# TC37XPD register map
Vendor: Infineon; Series: ATVMC; File version: 100
CPU: other r0p0, little endian, MPU, FPU, vendor SysTick, 4 interrupt priority bits
Registers are 32-bit, read-write, reset 0x0 unless marked. A register's access mark holds for its fields unless they carry their own. Offsets are from the block's base; [hi:lo] are bit positions; lines under a group give offsets from that group; {n}, {i} and the like mark numbered series; 'fields as' and 'values as' point back to an identical list.

## CAN1 — CAN
Base 0xF0210000
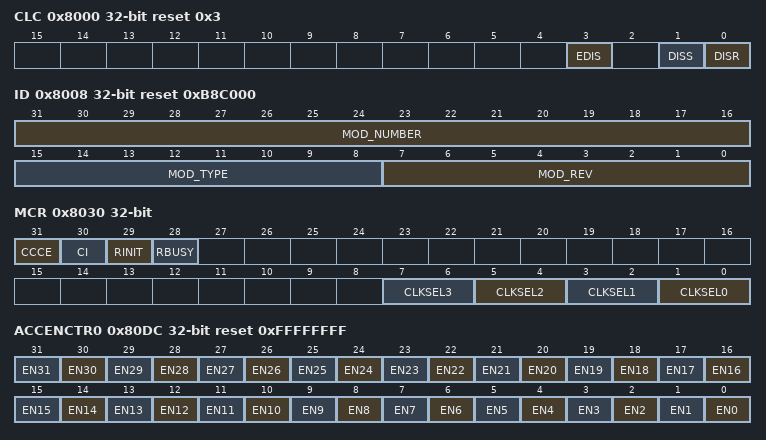
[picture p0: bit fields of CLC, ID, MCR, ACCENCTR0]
0x8000 CLC access per field reset 0x3 — CAN Clock Control Register resetvalue={Application Reset:0x3}
  [3] EDIS rw — Sleep Mode Disable Control EDIS. Used to control module s sleep mode.
  [1] DISS ro — Module Disable Status Bit DISS. Bit indicates the current status of the module.
  [0] DISR rw — Module Disable Request Bit DISR. Used for enable disable control of the module. The synchronous and asynchronous clock is switched on off Note that no register access is possible to any register while module is disabled. A disable request is granted if the M CAN clock is disabled or all M CAN nodes acknowledge the disable request.
0x8008 ID ro reset 0xB8C000 (reset mask 0xFFFFFF00) — Module Identification Register resetvalue={Application Reset:0x0B8C000}
  [31:16] MOD_NUMBER — Module Number Value MOD NUMBER. This bit field defines the MCMCAN module identification number 00B8 .
  [15:8] MOD_TYPE — Module Type MOD TYPE
  [7:0] MOD_REV — Module Revision Number MOD REV. MOD REV defines the revision number. The value of a module revision starts with 01 H first revision .
0x8030 MCR access per field — Module Control Register resetvalue={Application Reset:0x0}
  [31] CCCE rw — Clock and RAM Change Enable CCCE. Needs to be set to enable and disable the clocks.
  [30] CI rw — Change Init CI. Needs to be set to enable and disable clocks.
  [29] RINIT rw — RAM Init RINIT. This bit is not implemented in TC39x A step silicon. This bit is MCR.CI and MCR.CCCE protected. This bit starts the initialization of the RAM block to all 0x0. The RAM initialization is started only when this bit is changed from 0b to 1b and also RBUSY is 0b.
  [28] RBUSY ro — RAM BUSY RBUSY. This bit is not implemented in TC39x A step silicon. This bit shows that the RAM Initialization is running. This bit is set back to 0b by hardware when the RAM intialization is completed.
  [2n+1:2n] CLKSEL{n} rw (n=0..3) — Clock Select {n} CLKSEL{n}. This bitfield is MCR.CI and MCR.CCCE protected.
0x80DC ACCENCTR0 reset 0xFFFFFFFF — Access Enable Register Control 0 resetvalue={Application Reset:0x0FFFFFFFF}
  [n] EN{n} (n=0..31) — Access Enable for Master TAG ID 31 EN31. This bit enables write access to the module kernel addresses for transactions with the Master TAG ID y
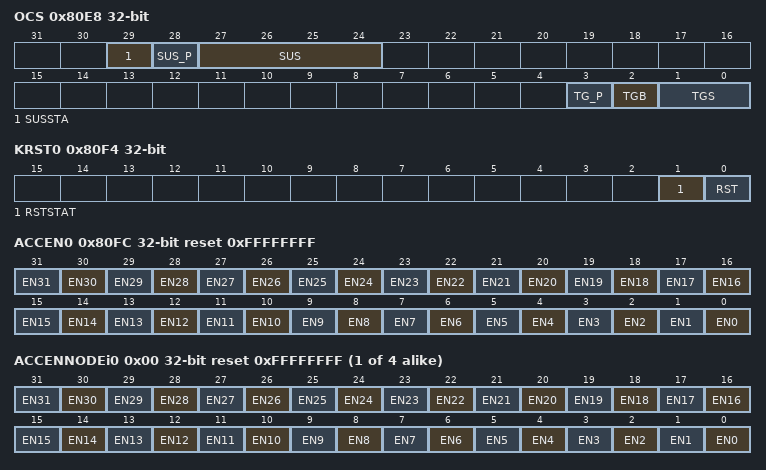
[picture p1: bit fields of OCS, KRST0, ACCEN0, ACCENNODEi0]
0x80E8 OCS access per field — OCDS Control and Status resetvalue={Debug Reset:0x0}
  [29] SUSSTA ro — Suspend State SUSSTA
  [28] SUS_P wo — SUS Write Protection SUS P. SUS is only written when SUS P is 1 otherwise unchanged. Read as 0.
  [27:24] SUS rw — OCDS Suspend Control SUS. Controls the sensitivity to the suspend signal coming from the OCDS Trigger Switch OTGS
  [3] TG_P wo — TGS TGB Write Protection TG P. TGS and TGB are only written when TG P is 1 otherwise unchanged. Read as 0.
  [2] TGB rw — OTGB0 1 Bus Select TGB
  [1:0] TGS rw — Trigger Set for OTGB0 1 TGS
0x80EC KRSTCLR wo — Kernel Reset Status Clear Register resetvalue={Application Reset:0x0}
  [0] CLR — Kernel Reset Status Clear CLR. Read always as 0.
0x80F0 KRST1 — Kernel Reset Register 1 resetvalue={Application Reset:0x0}
  [0] RST — Kernel Reset RST. This reset bit can be used to request for a kernel reset. The kernel reset will be executed if the reset bits of both kernel reset registers is set. The RST bit will be cleared reset to 0 by the BPI FPI after the kernel reset was executed.
0x80F4 KRST0 access per field — Kernel Reset Register 0 resetvalue={Application Reset:0x0}
  [1] RSTSTAT ro — Kernel Reset Status RSTSTAT. This bit indicates wether a kernel reset was executed or not. This bit is set by the BPI FPI after the execution of a kernel reset in the same clock cycle both reset bits. This bit can be cleared by writing with 180 1 180 to the CLR bit in the related KRSTCLR register.
  [0] RST rw — Kernel Reset RST. This reset bit can be used to request for a kernel reset. The kernel reset will be executed if the reset bits of both kernel registers are set. The RST bit will be cleared reset to 180 0 180 by the BPI FPI after the kernel reset was executed.
0x80FC ACCEN0 reset 0xFFFFFFFF — Access Enable Register 0 resetvalue={Application Reset:0x0FFFFFFFF}
  [n] EN{n} (n=0..31) — Access Enable for Master TAG ID 31 EN31. This bit enables write access to the module kernel addresses for transactions with the Master TAG ID y.
{0x8100+0x400*i} N[{i}] (i=0..3) group
  0x00 ACCENNODEi0 reset 0xFFFFFFFF — Access Enable Register CAN Node 0 0 resetvalue={Application Reset:0x0FFFFFFFF}
    fields as ACCENCTR0
  0x08 STARTADRi — Start Address Node 0 resetvalue={Application Reset:0x0}
    [15:2] START — Message RAM start START. The address within the RAM area of the MCMCAN of node i where the message RAM to be protected starts
  0x0C ENDADRi — End Address Node 0 resetvalue={Application Reset:0x0}
    [15:2] END — Message RAM end END. The address within the RAM area of the MCMCAN of node i where the message RAM to be protected ends
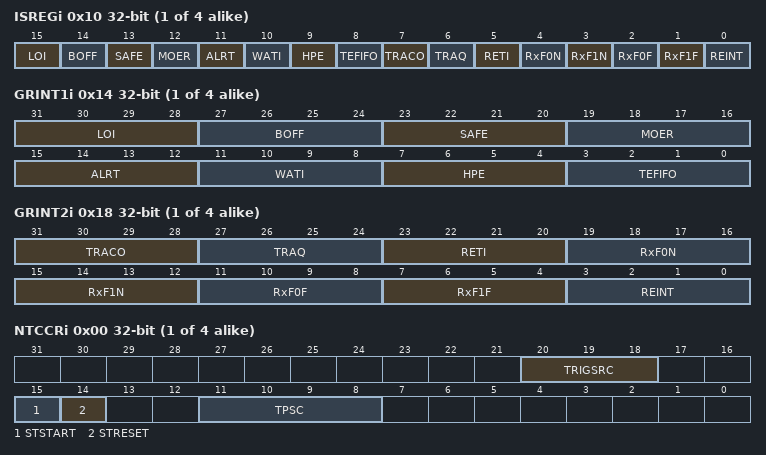
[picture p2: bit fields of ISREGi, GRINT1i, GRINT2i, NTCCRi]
  0x10 ISREGi ro — Interrupt Signalling Register 0 resetvalue={Application Reset:0x0}
    [15] LOI — Last Error Interrupt LOI
    [14] BOFF — Bus Off Interrupt BOFF
    [13] SAFE — The safety counter interrupt ELO SAFE
    [12] MOER — Module error interrupt MOER
    [11] ALRT — An alert interrupt ALRT
    [10] WATI — A watermark interrupt has been reached WATI
    [9] HPE — A high priority event interrupt HPE
    [8] TEFIFO — A Transmit Event FIFO Incident interrupt TEFIFO
    [7] TRACO — A transmission control event interrupt TRACO
    [6] TRAQ — A transmission queue event interrupt TRAQ
    [5] RETI — A receive timeout event interrupt RETI
    [4] RxF0N — Receive FIFO0 got a new message interrupt RxF0N
    [3] RxF1N — Receive FIFO1 got a new message interrupt RxF1N
    [2] RxF0F — Receive FIFO0 is full interrupt RxF0F
    [1] RxF1F — Receive FIFO1 is full interrupt RxF1F
    [0] REINT — A message stored in a receive buffer interrupt REINT
  0x14 GRINT1i — Interrupt routing for Groups 1 0 resetvalue={Application Reset:0x0}
    [31:28] LOI — Last Error Interrupts LOI. The interrupt sources IR.PED Protocol Error in Data Phase and IR.PEA Protocol Error in Arbitration Phase are signalled here.
    [27:24] BOFF — Bus Off has been reached BOFF. Mapped to IRi.BO flag indication the change in Bus Off status. To get out of bus off the CCCRn.INIT bit has to be reset.
    [23:20] SAFE — Safety counter overflow SAFE. The interrupt node for IR.ELO showing a safety counter overflow
    [19:16] MOER — Module errors MOER. IR.WDI watchdog interrupt and IR.MRAF message RAM access failure are mapped here.
    [15:12] ALRT — ALERTS ALRT. All kind of alerts are mapped here. IR.EW warning status IR.EP error passive IR.TSW timestamp wrap around IR.TEFL Transmit Event FIFO Element Lost IR.RF0L Receive FIFO 0 Message Lost IR.RF1L Receive FIFO 1 Message Lost . The following TTCAN error messages and warnings are also shown here TTIR. CER Configuration Error TTIR.AW Application Watchdog TTIR.WT Watch Trigger TTIR.IWT Initialization Watch Trigger TTIR.ELC Error Level Changed TTIR.SE2 Scheduling Error 2 TTIR.SE1 Scheduling Error TTIR.TXO Tx Count Overflow TTIR.TXU TX Count Underflow TTIR.GTE Global Time Error TTIR.GTD Global Time Discontinuity and TTIR.GTW Global Time Wrap
    [11:8] WATI — Watermark interrupts WATI. are mapped here IR.TEFW Transmit FIFO warning interrupt reached IR.RF1W Receive FIFO 1 warning interrupt reached . IR.RF0W Receive FIFO 0 warning interrupt reached
    [7:4] HPE — High Priority Events HPE. are mapped here giving IR.HPM an interrupt level
    [3:0] TEFIFO — Transmit Event FIFO Incidents TEFIFO. are mapped here. IR.TEFF Transmit Event FIFO Full and IR.TEFN Transmit Event FIFO New Entry
  0x18 GRINT2i — Interrupt routing for Groups 2 0 resetvalue={Application Reset:0x0}
    [31:28] TRACO — Interrupts of the transmission control TRACO. can be assigned here. IR.TCF Transmission Cancellation Finished and IR.TF Transmission Completed . As an additional information the copy of a local time event is shown here with TTIR.SWT Stop Watch Event . Further on the TTIR.TTMI Trigger Time Event Internal TTIR.RTMI Register Time Mark TTIR.SOG Start of Gap TTIR.CSM Change of Synchronization Mode TTIR.SMC Start Matrix Cycle and TTIR.SBC Start of Basic Cycle are shown here.
    [27:24] TRAQ — Transmission Queue Events TRAQ. can be assigned here. IR.TFE Transmission FIFO Empty
    [23:20] RETI — Receive Timeouts RETI. can be assigned here. IR.TOO time out event and TE Timer Event
    [19:16] RxF0N — IR.RF0N RxF0N. Receive FIFO0 new message assigned to an interrupt node
    [15:12] RxF1N — IR.RF1N RxF1N. Receive FIFO1 new message assigned to an interrupt node
    [11:8] RxF0F — IR.RF0F RxF0F. Receive FIFO0 full interrupt assigned to an interrupt node
    [7:4] RxF1F — IR.RF1F RxF1F. Receive FIFO1 full interrupt assigned to an interrupt node
    [3:0] REINT — Message stored in dedicated receive buffer interrupt IR.DRX REINT. is assigned to interrupt node.
  0x20 NT group
    0x00 NTCCRi — Node 0 Timer Clock Control Register resetvalue={Application Reset:0x0}
      [20:18] TRIGSRC — Trigger Source TRIGSRC. This bit selects the trigger source for the different modes in the node timer.
      [15] STSTART — Stamping Start STSTART. This bit is not implemented in TC39x A step silicon. This bit starts the external timer used for CAN FD messages. The source and the prescaler are identical to the timers A B C.
      [14] STRESET — Stamping Reset STRESET. This bit is not implemented in TC39x A step silicon. This bit gives the possibility to reset the time stamp for CAN FD messages.
      [11:8] TPSC — Timer Prescaler TPSC. The duration of one timer clock is given by TPSC 160 160 1 CAN bit times for all NTCCRi.TRIGSRC settings.
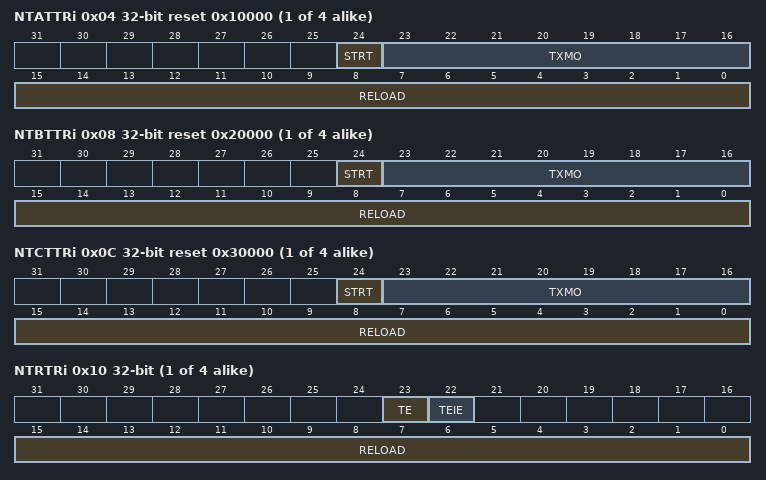
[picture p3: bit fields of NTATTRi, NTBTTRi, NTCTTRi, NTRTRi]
    0x04 NTATTRi access per field reset 0x10000 — Node 0 Timer A Transmit Trigger Register resetvalue={Application Reset:0x10000}
      [24] STRT rw — Timer Start STRT. This bit field controls the operation of the timer.
      [23:16] TXMO ro — Transmit Message Object TXMO. This transmit trigger is fixed to transmit buffer 1
      [15:0] RELOAD rw — Reload Value RELOAD. This bit field contains the reload value for the timer. The timer will restart when RELOAD is written.
    0x08 NTBTTRi access per field reset 0x20000 — Node 0 Timer B Transmit Trigger Register resetvalue={Application Reset:0x20000}
      [24] STRT rw — Timer Start STRT. This bit field controls the operation of the timer.
      [23:16] TXMO ro — Transmit Message Object TXMO. This transmit object is fixed to transmit buffer 2
      [15:0] RELOAD rw — Reload Value RELOAD. This bit field contains the reload value for the timer. The timer will restart when RELOAD is written.
    0x0C NTCTTRi access per field reset 0x30000 — Node 0 Timer C Transmit Trigger Register resetvalue={Application Reset:0x30000}
      [24] STRT rw — Timer Start STRT. This bit field controls the operation of the timer.
      [23:16] TXMO ro — Transmit Message Object TXMO. This transmit trigger is fixed to transmit buffer 3
      [15:0] RELOAD rw — Reload Value RELOAD. This bit field contains the reload value for the timer. The timer will restart when RELOAD is written.
    0x10 NTRTRi — Node 0 Timer Receive Timeout Register resetvalue={Application Reset:0x0}
      [23] TE — Timer Event TE. This flag is set on a node timer transition from 1 to 0 in Receive Timeout Mode. This bit must be reset i.e Write to 8216 0 8217 by software writing a 8216 1 8217 has no effect. An interrupt request is generated if TEIE 1.
      [22] TEIE — Timer Event Interrupt Enable TEIE. This bit enables the node timer event interrupt of CAN node i. Bit field GRINT2.RETI selects the interrupt output line which becomes activated at this type of interrupt.
      [15:0] RELOAD — Reload Value RELOAD. This bit field contains the reload value for the timer. The timer will start when RELOAD 8800 0 is written. After half the time of the RELOAD value the interrupt flags of the receive buffers will be cleared automatically to ensure that no message receive will be missed.
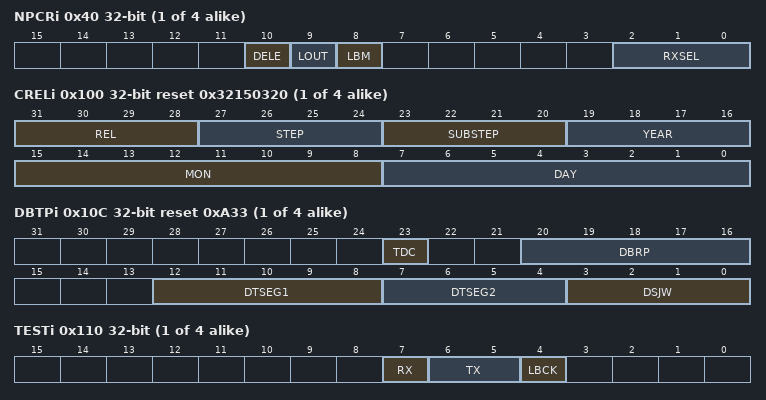
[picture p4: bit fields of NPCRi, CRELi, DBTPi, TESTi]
  0x40 NPCRi — Node 0 Port Control Register resetvalue={Application Reset:0x0}
    [10] DELE — Enable destructive read on ECR0.CEL DELE. If this bit is set the destructive read on ECRi.CEL and on the PSR register takes place. Meaning that with read access on ECRi the CEL is reset. The same is true for the PSR register for the bits PXE RFDF RBRS RESI LEC and DLEC. After the destructive read it is advised to reset the bit again.
    [9] LOUT — Loop Back Mode Out LOUT. This bit is not implemented in TC39x A step silicon. The loop back bus is switched to the external CAN bus of the node.
    [8] LBM — Loop Back Mode LBM
    [2:0] RXSEL — Receive Select RXSEL. RXSEL selects one out of 8 possible receive inputs. The CAN receive signal is performed by the selected input. see the device related chapter for RXSEL
  0x100 CRELi ro reset 0x32150320 (reset mask 0xFFFFFFFC) — Core Release Register 0 resetvalue={Application Reset:0x32150320,Application Reset:0x32150323,Application Reset:0x32150320}
    [31:28] REL — Core Release REL. One digit BCD coded.
    [27:24] STEP — Step of Core Release STEP. One digit BCD coded.
    [23:20] SUBSTEP — Sub step of Core Release SUBSTEP. One digit BCD coded.
    [19:16] YEAR — Time Stamp Year
    [15:8] MON — Time Stamp Month
    [7:0] DAY — Time Stamp Day
  0x104 ENDNi ro reset 0x87654321 — Endian Register 0 resetvalue={Application Reset:0x087654321}
    [31:0] ETV — Endianness Test Value ETV. The endianness test value is 0x87654321.
  0x10C DBTPi reset 0xA33 — Data Bit Timing Prescaler Register 0 resetvalue={Application Reset:0x0A33}
    [23] TDC — Transmitter Delay Compensation TDC. This bitfield is CCE and INIT protected. Writes will only have effect if both bits are set.
    [20:16] DBRP — Data Baud Rate Prescaler DBRP. This bitfield is CCE and INIT protected. Writes will only have effect if both bits are set. The value by which the oscillator frequency is divided for generating the bit time quanta. The bit time is built up from a multiple of this quanta. Valid values for the Baud Rate Prescaler are 8201 0 to 31. The actual interpretation by the hardware of this value is such that one more than the value programmed here is used.
    [12:8] DTSEG1 — Data time segment before sample point DTSEG1. This bitfield is CCE and INIT protected. Writes will only have effect if both bits are set. Valid values are 0 to 31. The actual interpretation by the hardware of this value is such that one more than the programmed value is used.
    [7:4] DTSEG2 — Data time segment after sample point DTSEG2. This bitfield is CCE and INIT protected. Writes will only have effect if both bits are set. Valid values are 0 to 15. The actual interpretation by the hardware of this value is such that one more than the programmed value is used.
    [3:0] DSJW — Data Re Synchronization Jump Width DSJW. This bitfield is CCE and INIT protected. Writes will only have effect if both bits are set. Valid values are 0 to 15. The actual interpretation by the hardware of this value is such that one more than the value programmed here is used.
  0x110 TESTi access per field (reset mask 0xFFFFFF7F) — Test Register 0 resetvalue={Application Reset:0x0}
    [7] RX ro — Receive Pin RX. Monitors the actual value of RX pin.
    [6:5] TX rw — Control of Transmit Pin TX. This bitfield is CCE and INIT protected. Writes will only have effect if both bits are set.
    [4] LBCK rw — Loop Back Mode LBCK. This bitfield is CCE and INIT protected. Writes will only have effect if both bits are set. This is the external loop back mode visible on the outside.
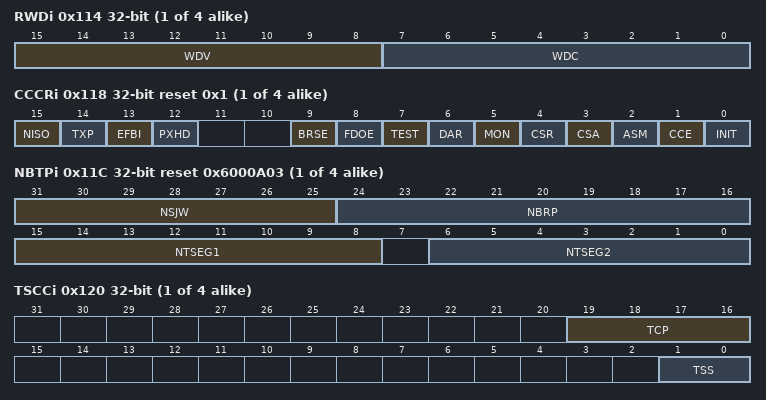
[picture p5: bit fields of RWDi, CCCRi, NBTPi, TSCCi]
  0x114 RWDi access per field — RAM Watchdog 0 resetvalue={Application Reset:0x0}
    [15:8] WDV ro — Watchdog Value WDV. Actual Message RAM Watchdog Counter Value.
    [7:0] WDC rw — Watchdog Configuration WDC. This bitfield is CCE and INIT protected. Writes will only have effect if both bits are set. Start value of the Message RAM Watchdog Counter. With the reset value of 00 the counter is disabled.
  0x118 CCCRi access per field reset 0x1 — CC Control Register 0 resetvalue={Application Reset:0x1}
    [15] NISO rw — Non ISO Operation NISO. If this bit is set the M CAN uses the CAN FD frame format as specified by the Bosch CAN FD Specification V1.0.
    [14] TXP rw — Transmit Pause TXP. This bitfield is CCE and INIT protected. Writes will only have effect if both bits are set. If this bit is set the M CAN pauses for two CAN bit times before starting the next transmission after itself has successfully transmitted a frame see CROSSREFERENCE .
    [13] EFBI rw — Edge Filtering during Bus Integration EFBI. This bitfield is CCE and INIT protected. Writes will only have effect if both bits are set.
    [12] PXHD rw — Protocol Exception Handling Disable PXHD. This bitfield is CCE and INIT protected. Writes will only have effect if both bits are set.
    [9] BRSE rw — Bit Rate Switch Enable BRSE. This bitfield is CCE and INIT protected. Writes will only have effect if both bits are set.
    [8] FDOE rw — FD Operation Enable FDOE. This bitfield is CCE and INIT protected. Writes will only have effect if both bits are set.
    [7] TEST rw — Test Mode Enable TEST. The TEST register can only be set if CCE INIT and TEST are set. Writes to test will only have effect if all three bits are set.
    [6] DAR rw — Disable Automatic Retransmission DAR. This bitfield is CCE and INIT protected. Writes will only have effect if both bits are set.
    [5] MON rw — Bus Monitoring Mode MON. Bit MON can only be set by the Host when both CCE and INIT are set to 8216 1 8217 . The bit can be reset by the Host at any time. The bus monitoring mode corresponds to the Analyzer Mode of the MultiCAN module.
    [4] CSR rw — Clock Stop Request CSR
    [3] CSA ro — Clock Stop Acknowledge CSA
    [2] ASM rw — Restricted Operation Mode ASM. Bit ASM can only be set by the Host when both CCE and INIT are set to 8216 1 8217 . In can also be set by the M CAN . The bit can be reset by the Host at any time. For a description of the Restricted Operation Mode see paragraph Restricted Operation Mode.
    [1] CCE rw — Configuration Change Enable CCE
    [0] INIT rw — Initialization INIT. Due to the synchronization mechanism between the two clock domains there may be a delay until the value written to INIT can be read back. Therefore the programmer has to assure that the previous value written to INIT has been accepted by reading INIT before setting INIT to a new value.
  0x11C NBTPi reset 0x6000A03 — Nominal Bit Timing Prescaler Register 0 resetvalue={Application Reset:0x6000A03}
    [31:25] NSJW — Re Synchronization Jump Width NSJW. This bitfield is CCE and INIT protected. Writes will only have effect if both bits are set. Valid values are 0 to 127. The actual interpretation by the hardware of this value is such that one more than the value programmed here is used.
    [24:16] NBRP — Baud Rate Prescaler NBRP. This bitfield is CCE and INIT protected. Writes will only have effect if both bits are set. The value by which the oscillator frequency is divided for generating the bit time quanta. The bit time is built up from a multiple of this quanta. Valid values for the Baud Rate Prescaler are 0 to 511. The actual interpretation by the hardware of this value is such that one more than the value programmed here is used.
    [15:8] NTSEG1 — Nominal Time segment before sample point NTSEG1. This bitfield is CCE and INIT protected. Writes will only have effect if both bits are set. Valid values are 1 to 255. The actual interpretation by the hardware of this value is such that one more than the programmed value is used.
    [6:0] NTSEG2 — Nominal Time segment after sample point NTSEG2. This bitfield is CCE and INIT protected. Writes will only have effect if both bits are set. Valid values are 1 to 127. The actual interpretation by the hardware of this value is such that one more than the programmed value is used.
  0x120 TSCCi — Timestamp Counter Configuration 0 resetvalue={Application Reset:0x0}
    [19:16] TCP — Timestamp Counter Prescaler TCP. This bitfield is CCE and INIT protected. Writes will only have effect if both bits are set. Configures the timestamp and timeout counters time unit in multiples of CAN bit times 8201 1 8230 16 8201 . The actual interpretation by the hardware of this value is such that one more than the value programmed here is used. With CAN FD an external counter is required for timestamp generation TSS 8220 10 8221
    [1:0] TSS — Time segment before sample point TSS. This bitfield is CCE and INIT protected. Writes will only have effect if both bits are set.
  0x124 TSCVi — Timestamp Counter Value 0 resetvalue={Application Reset:0x0}
    [15:0] TSC — Timestamp Counter TSC. The internal external Timestamp Counter value is captured on start of frame both Rx and Tx . When TSCC.TSS 8220 01 8221 the Timestamp Counter is incremented in multiples of CAN bit times 8201 1 8230 16 8201 depending on the configuration of TSCC.TCP. A wrap around sets interrupt flag IR.TSW. Write access resets the counter to zero. When TSCC.TSS 160 160 8220 10 8221 TSC reflects the external Timestamp Counter value. A write access has no impact. A 8220 wrap around 8221 is a change of the Timestamp Counter value from non zero to zero not caused by write access to TSCV.
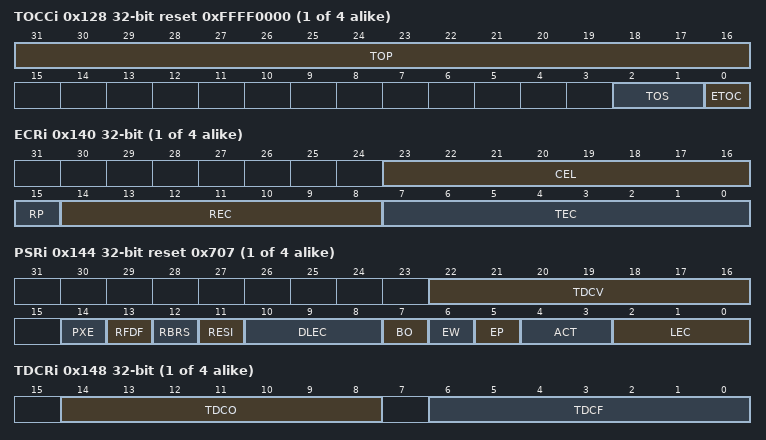
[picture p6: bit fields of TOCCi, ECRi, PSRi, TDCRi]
  0x128 TOCCi reset 0xFFFF0000 — Timeout Counter Configuration 0 resetvalue={Application Reset:0x0FFFF0000}
    [31:16] TOP — Timeout Period TOP. This bitfield is CCE and INIT protected. Writes will only have effect if both bits are set. Start value of the Timeout Counter down counter . Configures the Timeout Period.
    [2:1] TOS — Timeout Select TOS. This bitfield is CCE and INIT protected. Writes will only have effect if both bits are set. When operating in Continuous mode a write to TOCV presets the counter to the value configured by TOCC.TOP and continues down counting. When the Timeout Counter is controlled by one of the FIFOs an empty FIFO presets the counter to the value configured by TOCC.TOP. Down counting is started when the first FIFO element is stored.
    [0] ETOC — Enable Timeout Counter ETOC. This bitfield is CCE and INIT protected. Writes will only have effect if both bits are set. For use of timeout function with CAN FD see chapter Timeout Counter.
  0x12C TOCVi reset 0xFFFF — Timeout Counter Value 0 resetvalue={Application Reset:0x0FFFF}
    [15:0] TOC — Timeout Counter TOC. The Timeout Counter is decremented in multiples of CAN bit times 8201 1 8230 16 8201 depending on the configuration of TSCC.TCP. When decremented to zero interrupt flag IR.TOO is set and the Timeout Counter is stopped. Start and reset restart conditions are configured via TOCC.TOS. Any write access will lead to clearing of the counter.
  0x140 ECRi ro — Error Counter Register 0 resetvalue={Application Reset:0x0}
    [23:16] CEL — CAN Error Logging CEL. The counter is incremented each time when a CAN protocol error causes the Transmit Error Counter or the Receive Error Counter to be incremented. It is reset by read access to CEL. The counter stops at 0xFF the next increment of TEC or REC sets interrupt flag IR.ELO. The counter is reset on read if the bit NPCRi.DELE is set for the node.
    [15] RP — Receive Error Passive RP
    [14:8] REC — Receive Error Counter REC. Actual state of the Receive Error Counter values between 0 and 127 When CCCR.ASM is set the CAN protocol controller does not increment TEC and REC when a CAN protocol error is detected but CEL is still incremented.
    [7:0] TEC — Transmit Error Counter TEC. Actual state of the Transmit Error Counter values between 0 and 255 When CCCR.ASM is set the CAN protocol controller does not increment TEC and REC when a CAN protocol error is detected but CEL is still incremented.
  0x144 PSRi ro reset 0x707 — Protocol Status Register 0 resetvalue={Application Reset:0x707}
    [22:16] TDCV — Transmitter Delay Compensation Value TDCV. Position of the secondary sample point defined by the sum of the measured delay from TX to RX and TDCR.TDCO. The SSP position is in the data phase the number of mtq between the start of the transmitted bit and the secondary sample point. Valid values are 0 to 127 mtq.
    [14] PXE — Protocol Exception Event PXE. This bit is reset after read access if NPCRi.DELE is set.
    [13] RFDF — Received a CAN FD Message RFDF. This bit is set independent of acceptance filtering. This bit is reset after read access if NPCRi.DELE is set.
    [12] RBRS — BRS flag of last received CAN FD Message RBRS. This bit is set together with REDF independent of acceptance filtering. This bit is reset after read access if NPCRi.DELE is set.
    [11] RESI — ESI flag of last received CAN FD Message RESI. This bit is set together with REDF independent of acceptance filtering. This bit is reset after read access if NPCRi.DELE is set.
    [10:8] DLEC — Data Phase Last Error Code DLEC. Type of last error that occurred in the data phase of a CAN FD format frame with its BRS flag set. Coding is the same as for LEC. This field will be cleared to zero when a CAN FD format frame with its BRS flag set has been transferred reception or transmission without error. This bit field is set to 0x7 on read if NPCRi.DELE is set. When a frame in CAN FD format has reached the data phase with BRS flag set the next CAN event error or valid frame will be shown in DLEC instead of LEC. An error in a fixed stuff bit of a CAN FD CRC sequence will be shown as a Form Error not Stuff Error.
    [7] BO — Bus Off Status BO
    [6] EW — Warning Status EW
    [5] EP — Error Passive EP
    [4:3] ACT — Activity ACT. Monitors the module s CAN communication state. ACT is set to 00 by a Protocol Exception Event.
    [2:0] LEC — Last Error Code LEC. The LEC indicates the type of the last error to occur on the CAN bus. This field will be cleared to 8216 0 8217 when a message has been transferred reception or transmission without error. This bit field is set to 0x7 on read if NPCRi.DELE is set. The Bus Off recovery sequence see ISO11898 1 cannot be shortened by setting or resetting CCCR.INIT. If the device goes Bus Off it will set CCCR.INIT of its own accord stopping all bus activities. Once CCCR.INIT has been cleared by the CPU the device will then wait for 129 occurrences of Bus Idle 129 11 consecutive recessive bits before resuming normal operation. At the end of the Bus Off recovery sequence the Error Management Counters will be reset. During the waiting time after the resetting of CCCR.INIT each time a sequence of 11 recessive bits has been monitored a Bit0Error code is written to PSR.LEC enabling the CPU to readily check up whether the CAN bus is stuck at dominant or continuously disturbed and to monitor the Bus Off recovery sequence. ECR.REC is used to count these sequences.
  0x148 TDCRi — Transmitter Delay Compensation Register 0 resetvalue={Application Reset:0x0}
    [14:8] TDCO — Transmitter Delay Compensation Offset TDCO. This bitfield is CCE and INIT protected. Writes will only have effect if both bits are set. Offset value defining the distance between the measured delay from TX to RX and the secondary sample point. Valid values are 0 to 127 mtq. The duration of one mtq is equal to the fASYNi clock period.
    [6:0] TDCF — Transmitter Delay Compensation Filter Window Length TDCF. This bitfield is CCE and INIT protected. Writes will only have effect if both bits are set. Defines the minimum value for the Secondary Sample Point position dominant edges on RX that would result in an earlier Secondary Sample Point position are ignored for transmitter delay measurement. This feature is enabled when TDCF is configured to a value greater than TDCO. Valid values are from 0 to 127 mtq.
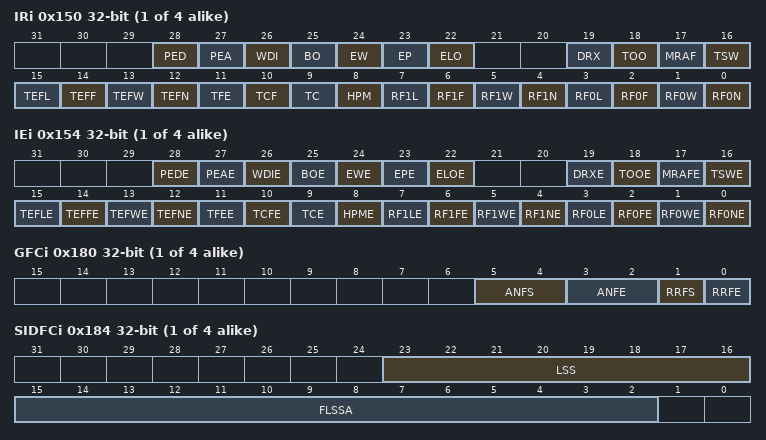
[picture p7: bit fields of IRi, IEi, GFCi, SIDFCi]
  0x150 IRi — Interrupt Register 0 resetvalue={Application Reset:0x0}
    [28] PED — Protocol Error in Data Phase PED. Data Bit Time is used
    [27] PEA — Protocol Error in Arbitration Phase PEA. Nominal Bit Time is used
    [26] WDI — Watchdog Interrupt WDI
    [25] BO — Bus Off Status BO
    [24] EW — Warning Status EW
    [23] EP — Error Passive EP
    [22] ELO — Error Logging Overflow ELO
    [19] DRX — Message stored to Dedicated Rx Buffer DRX. The flag is set whenever a received message has been stored into a dedicated Rx Buffer.
    [18] TOO — Timeout Occurred TOO
    [17] MRAF — Message RAM Access Failure MRAF. The flag is set when the Rx Handler has not completed acceptance filtering or storage of an accepted message until the arbitration field of the following message has been received. In this case acceptance filtering or message storage is aborted and the Rx Handler starts processing of the following message. was not able to write a message to the Message RAM. In this case message storage is aborted. In both cases the FIFO put index is not updated resp. the New Data flag for a dedicated Rx Buffer is not set a partly stored message is overwritten when the next message is stored to this location. The flag is also set when the Tx Handler was not able to read a message from the Message RAM in time. In this case message transmission is aborted. In case of a Tx Handler access failure the M CAN is switched into Restricted Operation Mode. To leave Restricted Operation Mode the Host CPU has to reset CCCR.ASM.
    [16] TSW — Timestamp Wraparound TSW
    [15] TEFL — Tx Event FIFO Element Lost TEFL
    [14] TEFF — Tx Event FIFO Full TEFF
    [13] TEFW — Tx Event FIFO Watermark Reached TEFW
    [12] TEFN — Tx Event FIFO New Entry TEFN
    [11] TFE — Tx FIFO Empty TFE
    [10] TCF — Transmission Cancellation Finished TCF
    [9] TC — Transmission Completed TC
    [8] HPM — High Priority Message HPM
    [7] RF1L — Rx FIFO 1 Message Lost RF1L
    [6] RF1F — Rx FIFO 1 Full RF1F
    [5] RF1W — Rx FIFO 1 Watermark Reached RF1W
    [4] RF1N — Rx FIFO 1 New Message RF1N
    [3] RF0L — Rx FIFO 0 Message Lost RF0L
    [2] RF0F — Rx FIFO 0 Full RF0F
    [1] RF0W — Rx FIFO 0 Watermark Reached RF0W
    [0] RF0N — Rx FIFO 0 New Message RF0N
  0x154 IEi — Interrupt Enable 0 resetvalue={Application Reset:0x0}
    [28] PEDE — Protocol Error in Data Phase Enable PEDE
    [27] PEAE — Protocol Error in Arbitration Phase Enable PEAE
    [26] WDIE — Watchdog Interrupt Enable WDIE
    [25] BOE — Bus Off Status Interrupt Enable BOE
    [24] EWE — Warning Status Interrupt Enable EWE
    [23] EPE — Error Passive Interrupt Enable EPE
    [22] ELOE — Error Logging Overflow Interrupt Enable ELOE
    [19] DRXE — Message stored to Dedicated Rx Buffer Interrupt Enable DRXE
    [18] TOOE — Timeout Occurred Interrupt Enable TOOE
    [17] MRAFE — Message RAM Access Failure Interrupt Enable MRAFE
    [16] TSWE — Timestamp Wraparound Interrupt Enable TSWE
    [15] TEFLE — Tx Event FIFO Element Lost Interrupt Enable TEFLE
    [14] TEFFE — Tx Event FIFO Full Interrupt Enable TEFFE
    [13] TEFWE — Tx Event FIFO Watermark Reached Interrupt Enable TEFWE
    [12] TEFNE — Tx Event FIFO New Entry Interrupt Enable TEFNE
    [11] TFEE — Tx FIFO Empty Interrupt Enable TFEE
    [10] TCFE — Transmission Cancellation Finished Interrupt Enable TCFE
    [9] TCE — Transmission Completed Interrupt Enable TCE
    [8] HPME — High Priority Message Interrupt Enable HPME
    [7] RF1LE — Rx FIFO 1 Message Lost Interrupt Enable RF1LE
    [6] RF1FE — Rx FIFO 1 Full Interrupt Enable RF1FE
    [5] RF1WE — Rx FIFO 1 Watermark Reached Interrupt Enable RF1WE
    [4] RF1NE — Rx FIFO 1 New Message Interrupt Enable RF1NE
    [3] RF0LE — Rx FIFO 0 Message Lost Interrupt Enable RF0LE
    [2] RF0FE — Rx FIFO 0 Full Interrupt Enable RF0FE
    [1] RF0WE — Rx FIFO 0 Watermark Reached Interrupt Enable RF0WE
    [0] RF0NE — Rx FIFO 0 New Message Interrupt Enable RF0NE
  0x180 GFCi — Global Filter Configuration 0 resetvalue={Application Reset:0x0}
    [5:4] ANFS — Accept Non matching Frames Standard ANFS. This bitfield is CCE and INIT protected. Writes will only have effect if both bits are set. Defines how received messages with 11 bit IDs that do not match any element of the filter list are treated.
    [3:2] ANFE — Accept Non matching Frames Extended ANFE. This bitfield is CCE and INIT protected. Writes will only have effect if both bits are set. Defines how received messages with 29 bit IDs that do not match any element of the filter list are treated.
    [1] RRFS — Reject Remote Frames Standard RRFS. This bitfield is CCE and INIT protected. Writes will only have effect if both bits are set.
    [0] RRFE — Reject Remote Frames Extended RRFE. This bitfield is CCE and INIT protected. Writes will only have effect if both bits are set.
  0x184 SIDFCi — Standard ID Filter Configuration 0 resetvalue={Application Reset:0x0}
    [23:16] LSS — List Size Standard LSS. This bitfield is CCE and INIT protected. Writes will only have effect if both bits are set.
      255=rest255 (128 Message ID filter elements)
    [15:2] FLSSA — Filter List Standard Start Address FLSSA. This bitfield is CCE and INIT protected. Writes will only have effect if both bits are set. Start address of standard Message ID filter list 32 bit word address .
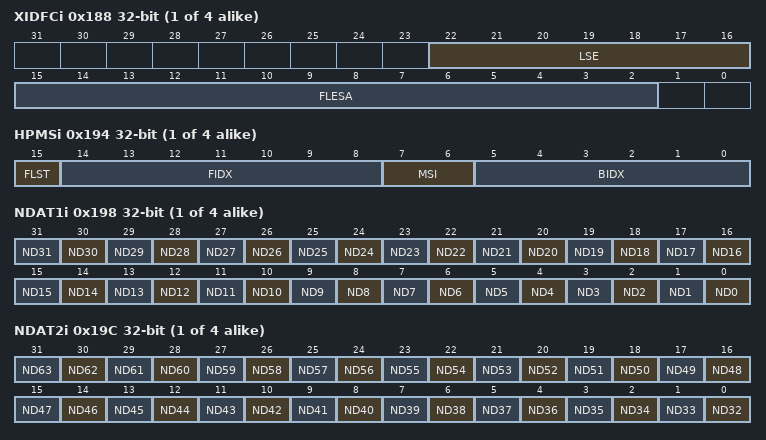
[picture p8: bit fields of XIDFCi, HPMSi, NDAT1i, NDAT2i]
  0x188 XIDFCi — Extended ID Filter Configuration 0 resetvalue={Application Reset:0x0}
    [22:16] LSE — List Size Extended LSE. This bitfield is CCE and INIT protected. Writes will only have effect if both bits are set.
      127=rest127 (64 extended Message ID filter elements)
    [15:2] FLESA — Filter List Extended Start Address FLESA. This bitfield is CCE and INIT protected. Writes will only have effect if both bits are set. Start address of extended Message ID filter list 32 bit word addess .
  0x190 XIDAMi reset 0x1FFFFFFF — Extended ID AND Mask 0 resetvalue={Application Reset:0x1FFFFFFF}
    [28:0] EIDM — Extended ID Mask EIDM. This bitfield is CCE and INIT protected. Writes will only have effect if both bits are set. For acceptance filtering of extended frames the Extended ID AND Mask is ANDed with the Message ID of a received frame. Intended for masking of 29 bit IDs in SAE J1939. With the reset value of all bits set to one the mask is not active.
  0x194 HPMSi ro — High Priority Message Status 0 resetvalue={Application Reset:0x0}
    [15] FLST — Filter List FLST. Indicates the filter list of the matching filter element.
    [14:8] FIDX — Filter Index FIDX. Index of matching filter element. Range is 0 to SIDFC.LSS 160 160 1 resp. XIDFC.LSE 160 160 1.
    [7:6] MSI — Message Storage Indicator MSI
    [5:0] BIDX — Buffer Index BIDX. Index of Rx FIFO element to which the message was stored. Only valid when MSI 1 1 .
  0x198 NDAT1i — New Data 1 0 resetvalue={Application Reset:0x0}
    [n] ND{n} (n=0..31) — New Data in Rx Buffer 31 ND. The flag is set when the respective Rx Buffer has been updated from a received frame. The flags remain set until the Host clears them. A flag is cleared by writing a 8220 1 8221 to the corresponding bit position. Writing a 8220 0 8221 has no effect.
  0x19C NDAT2i — New Data 2 0 resetvalue={Application Reset:0x0}
    [n-32] ND{n} (n=32..63) — New Data in Rx Buffer 63 ND. The flag is set when the respective Rx Buffer has been updated from a received frame. The flags remain set until the Host clears them. A flag is cleared by writing a 8220 1 8221 to the corresponding bit position. Writing a 8220 0 8221 has no effect.
  0x1A0 RX group
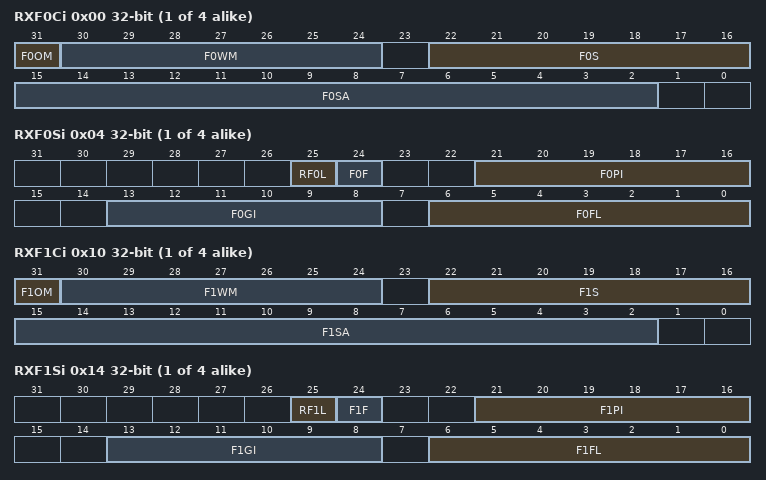
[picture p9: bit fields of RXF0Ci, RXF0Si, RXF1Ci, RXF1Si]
    0x00 RXF0Ci — Rx FIFO 0 Configuration 0 resetvalue={Application Reset:0x0}
      [31] F0OM — FIFO 0 Operation Mode F0OM. This bitfield is CCE and INIT protected. Writes will only have effect if both bits are set. FIFO 0 can be operated in blocking or in overwrite mode see CROSSREFERENCE .
      [30:24] F0WM — Rx FIFO 0 Watermark F0WM. This bitfield is CCE and INIT protected. Writes will only have effect if both bits are set.
        127=rest127 (Watermark interrupt disabled)
      [22:16] F0S — Rx FIFO 0 Size F0S. This bitfield is CCE and INIT protected. Writes will only have effect if both bits are set.
        127=rest127 (64 Rx FIFO 0 elements)
      [15:2] F0SA — Rx FIFO 0 Start Address F0SA. This bitfield is CCE and INIT protected. Writes will only have effect if both bits are set. Start address of Rx FIFO 0 in Message RAM 32 bit word address see CROSSREFERENCE .
    0x04 RXF0Si ro — Rx FIFO 0 Status 0 resetvalue={Application Reset:0x0}
      [25] RF0L — Rx FIFO 0 Message Lost RF0L. This bit is a copy of interrupt flag IR.RF0L. When IR.RF0L is reset this bit is also reset. Overwriting the oldest message when RXF0C.F0OM 1 will not set this flag.
      [24] F0F — Rx FIFO 0 Full F0F
      [21:16] F0PI — Rx FIFO 0 Put Index F0PI. Rx FIFO 0 write index pointer range 0 to 63.
      [13:8] F0GI — Rx FIFO 0 Get Index F0GI. Rx FIFO 0 read index pointer range 0 to 63.
      [6:0] F0FL — Rx FIFO 0 Fill Level F0FL. Number of elements stored in Rx FIFO 0 range 0 to 64.
    0x08 RXF0Ai — Rx FIFO 0 Acknowledge 0 resetvalue={Application Reset:0x0}
      [5:0] F0AI — Rx FIFO 0 Acknowledge Index F0AI. After the Host has read a message or a sequence of messages from Rx FIFO 0 it has to write the buffer index of the last element read from Rx FIFO 0 to F0AI. This will set the Rx FIFO 0 Get Index RXF0S.F0GI to F0AI 1 and update the FIFO 0 Fill Level RXF0S.F0FL.
    0x0C RXBCi — Rx Buffer Configuration 0 resetvalue={Application Reset:0x0}
      [15:2] RBSA — Rx Buffer Start Address RBSA. This bitfield is CCE and INIT protected. Writes will only have effect if both bits are set. Configures the start address of the Rx Buffers section in the Message RAM 32 bit word address . Also used to reference debug messages A B C.
    0x10 RXF1Ci — Rx FIFO 1 Configuration 0 resetvalue={Application Reset:0x0}
      [31] F1OM — FIFO 1 Operation Mode F1OM. This bitfield is CCE and INIT protected. Writes will only have effect if both bits are set. FIFO 1 can be operated in blocking or in overwrite mode.
      [30:24] F1WM — Rx FIFO 1 Watermark F1WM. This bitfield is CCE and INIT protected. Writes will only have effect if both bits are set.
        127=rest127 (Watermark interrupt disabled)
      [22:16] F1S — Rx FIFO 1 Size F1S. This bitfield is CCE and INIT protected. Writes will only have effect if both bits are set.
        127=rest127 (64 Rx FIFO 1 elements)
      [15:2] F1SA — Rx FIFO 1 Start Address F1SA. This bitfield is CCE and INIT protected. Writes will only have effect if both bits are set. Start address of Rx FIFO 1 in Message RAM 32 bit word address .
    0x14 RXF1Si ro — Rx FIFO 1 Status 0 resetvalue={Application Reset:0x0}
      [25] RF1L — Rx FIFO 1 Message Lost RF1L. This bit is a copy of interrupt flag IR.RF1L. When IR.RF1L is reset this bit is also reset. Overwriting the oldest message when RXF1C.F1OM 1 will not set this flag.
      [24] F1F — Rx FIFO 1 Full F1F
      [21:16] F1PI — Rx FIFO 1 Put Index F1PI. Rx FIFO 1 write index pointer range 0 to 63.
      [13:8] F1GI — Rx FIFO 1 Get Index F1GI. Rx FIFO 1 read index pointer range 0 to 63.
      [6:0] F1FL — Rx FIFO 1 Fill Level F1FL. Number of elements stored in Rx FIFO 1 range 0 to 64.
    0x18 RXF1Ai — Rx FIFO 1 Acknowledge 0 resetvalue={Application Reset:0x0}
      [5:0] F1AI — Rx FIFO 1 Acknowledge Index F1AI. After the Host has read a message or a sequence of messages from Rx FIFO 1 it has to write the buffer index of the last element read from Rx FIFO 1 to F1AI. This will set the Rx FIFO 1 Get Index RXF1S.F1GI to F1AI 1 and update the FIFO 1 Fill Level RXF1S.F1FL
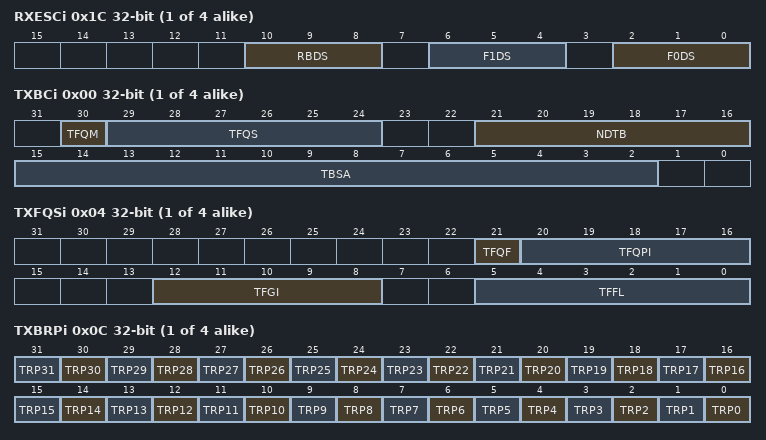
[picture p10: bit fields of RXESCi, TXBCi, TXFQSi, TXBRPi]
    0x1C RXESCi — Rx Buffer FIFO Element Size Configuration 0 resetvalue={Application Reset:0x0}
      [10:8] RBDS — Rx Buffer Data Field Size RBDS. This bitfield is CCE and INIT protected. Writes will only have effect if both bits are set.
      [6:4] F1DS — Rx FIFO 1 Data Field Size F1DS. This bitfield is CCE and INIT protected. Writes will only have effect if both bits are set.
      [2:0] F0DS — Rx FIFO 0 Data Field Size F0DS. This bitfield is CCE and INIT protected. Writes will only have effect if both bits are set. In case the data field size of an accepted CAN frame exceeds the data field size configured for the matching Rx Buffer or Rx FIFO only the number of bytes as configured by RXESC are stored to the Rx Buffer resp. Rx FIFO element. The rest of the frame s data field is ignored.
  0x1C0 TX group
    0x00 TXBCi — Tx Buffer Configuration 0 resetvalue={Application Reset:0x0}
      [30] TFQM — Tx FIFO Queue Mode TFQM. This bitfield is CCE and INIT protected. Writes will only have effect if both bits are set.
      [29:24] TFQS — Transmit FIFO Queue Size TFQS. This bitfield is CCE and INIT protected. Writes will only have effect if both bits are set.
        63=rest63 (32 Tx Buffers used for Tx FIFO Queue)
      [21:16] NDTB — Number of Dedicated Transmit Buffers NDTB. This bitfield is CCE and INIT protected. Writes will only have effect if both bits are set. Be aware that the sum of TFQS and NDTB may be not greater than 32. There is no check for erroneous configurations. The Tx Buffers section in the Message RAM starts with the dedicated Tx Buffers.
        63=rest63 (32 Dedicated Tx Buffers)
      [15:2] TBSA — Tx Buffers Start Address TBSA. This bitfield is CCE and INIT protected. Writes will only have effect if both bits are set. Start address of Tx Buffers section in Message RAM 32 bit word address .
    0x04 TXFQSi ro — Tx FIFO Queue Status 0 resetvalue={Application Reset:0x0}
      [21] TFQF — Tx FIFO Queue Full TFQF
      [20:16] TFQPI — Tx FIFO Queue Put Index TFQPI. Tx FIFO Queue write index pointer range 0 to 31.
      [12:8] TFGI — Tx FIFO Get Index TFGI. Tx FIFO read index pointer range 0 to 31. Read as zero when Tx Queue operation is configured TXBC.TFQM 1 .
      [5:0] TFFL — Tx FIFO Free Level TFFL. Number of consecutive free Tx FIFO elements starting from TFGI range 0 to 32. Read as zero when Tx Queue operation is configured TXBC.TFQM 8216 1 8217 In case of mixed configurations where dedicated Tx Buffers are combined with a Tx FIFO or a Tx Queue the Put and Get Indices indicate the number of the Tx Buffer starting with the first dedicated Tx Buffers. Example For a configuration of 12 dedicated Tx Buffers and a Tx FIFO of 20 Buffers a Put Index of 15 points to the fourth buffer of the Tx FIFO.
    0x08 TXESCi — Tx Buffer Element Size Configuration 0 resetvalue={Application Reset:0x0}
      [2:0] TBDS — Tx Buffer Data Field Size TBDS. This bitfield is CCE and INIT protected. Writes will only have effect if both bits are set. In case the data length code DLC of a Tx Buffer element is configured to a value higher than the Tx Buffer data field size TXESC.TBDS the bytes not defined by the Tx Buffer are transmitted as 0xCC padding bytes .
    0x0C TXBRPi ro — Tx Buffer Request Pending 0 resetvalue={Application Reset:0x0}
      [n] TRP{n} (n=0..31) — Transmission Request Pending Tx Buffer 31 TRP
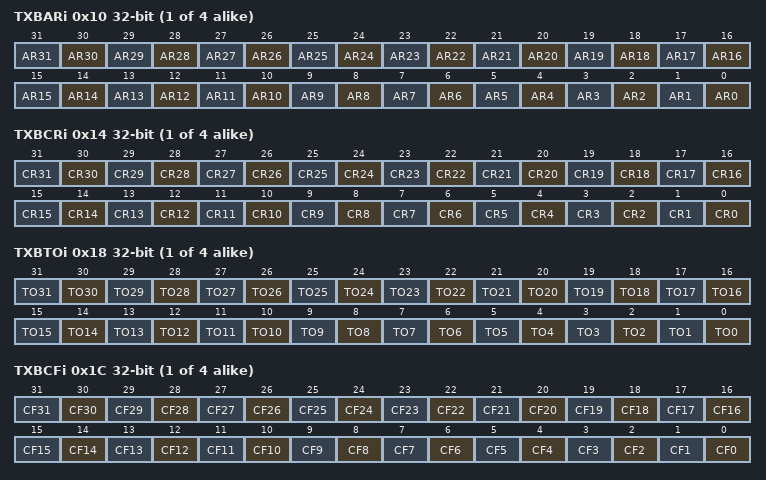
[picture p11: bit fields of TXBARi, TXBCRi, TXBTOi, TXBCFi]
    0x10 TXBARi — Tx Buffer Add Request 0 resetvalue={Application Reset:0x0}
      [n] AR{n} (n=0..31) — Add Request Tx Buffer 31 AR
    0x14 TXBCRi — Tx Buffer Cancellation Request 0 resetvalue={Application Reset:0x0}
      [n] CR{n} (n=0..31) — Cancellation Request Tx Buffer 31 CR
    0x18 TXBTOi ro — Tx Buffer Transmission Occurred 0 resetvalue={Application Reset:0x0}
      [n] TO{n} (n=0..31) — Transmission Occurred Tx Buffer 31 TO
    0x1C TXBCFi ro — Tx Buffer Cancellation Finished 0 resetvalue={Application Reset:0x0}
      [n] CF{n} (n=0..31) — Cancellation Finished Tx Buffer 31 CF
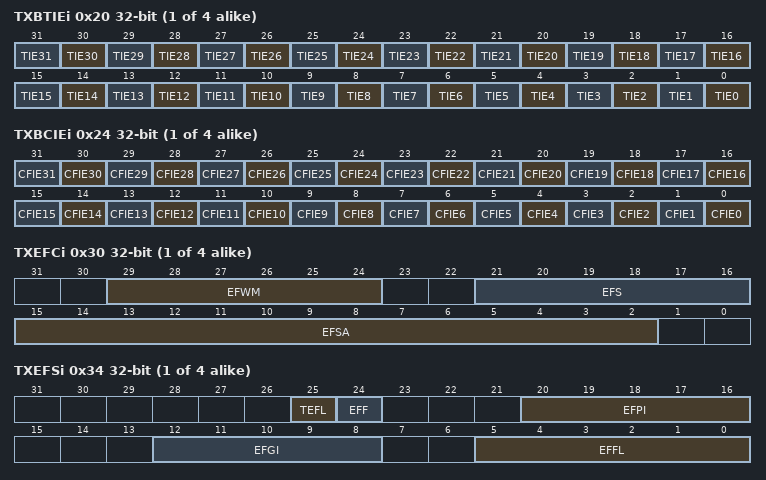
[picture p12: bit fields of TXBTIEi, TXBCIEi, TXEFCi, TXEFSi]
    0x20 TXBTIEi — Tx Buffer Transmission Interrupt Enable 0 resetvalue={Application Reset:0x0}
      [n] TIE{n} (n=0..31) — Transmission Interrupt Enable Tx Buffer 31 TIE
    0x24 TXBCIEi — Tx Buffer Cancellation Finished Interrupt Enable 0 resetvalue={Application Reset:0x0}
      [n] CFIE{n} (n=0..31) — Cancellation Finished Interrupt Enable Tx Buffer 31 CFIE
    0x30 TXEFCi — Tx Event FIFO Configuration 0 resetvalue={Application Reset:0x0}
      [29:24] EFWM — Event FIFO Watermark EFWM. This bitfield is CCE and INIT protected. Writes will only have effect if both bits are set.
        63=rest63 (Watermark interrupt disabled)
      [21:16] EFS — Event FIFO Size EFS. This bitfield is CCE and INIT protected. Writes will only have effect if both bits are set. The Tx Event FIFO elements are indexed from 0 to EFS 1
        63=rest63 (32 Tx Event FIFO elements)
      [15:2] EFSA — Event FIFO Start Address EFSA. This bitfield is CCE and INIT protected. Writes will only have effect if both bits are set. Start address of Tx Event FIFO in Message RAM 32 bit word address .
    0x34 TXEFSi ro — Tx Event FIFO Status 0 resetvalue={Application Reset:0x0}
      [25] TEFL — Tx Event FIFO Element Lost TEFL. This bit is a copy of interrupt flag IR.TEFL. When IR.TEFL is reset this bit is also reset.
      [24] EFF — Event FIFO Full EFF
      [20:16] EFPI — Event FIFO Put Index EFPI. Tx Event FIFO write index pointer range 0 to 31.
      [12:8] EFGI — Event FIFO Get Index EFGI. Tx Event FIFO read index pointer range 0 to 31.
      [5:0] EFFL — Event FIFO Fill Level EFFL. Number of elements stored in Tx Event FIFO range 0 to 32.
    0x38 TXEFAi — Tx Event FIFO Acknowledge 0 resetvalue={Application Reset:0x0}
      [4:0] EFAI — Event FIFO Acknowledge Index EFAI. After the Host has read an element or a sequence of elements from the Tx Event FIFO it has to write the index of the last element read from Tx Event FIFO to EFAI. This will set the Tx Event FIFO Get Index TXEFS.EFGI to EFAI 160 160 1 and update the FIFO 0 Fill Level TXEFS.EFFL.
